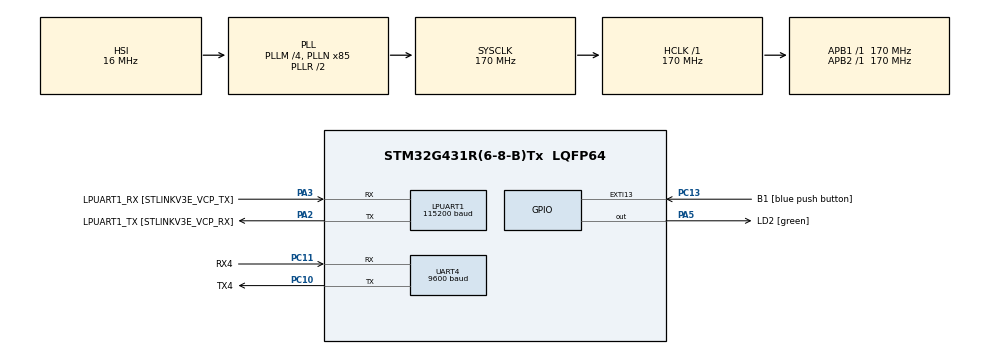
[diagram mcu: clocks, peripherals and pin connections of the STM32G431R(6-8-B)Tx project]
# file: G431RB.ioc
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Dma.Request0=UART4_RX
Dma.Request1=UART4_TX
Dma.UART4_RX.0.Direction=DMA_PERIPH_TO_MEMORY
Dma.UART4_RX.0.EventEnable=DISABLE
Dma.UART4_RX.0.Instance=DMA1_Channel1
Dma.UART4_RX.0.MemDataAlignment=DMA_MDATAALIGN_BYTE
Dma.UART4_RX.0.MemInc=DMA_MINC_ENABLE
Dma.UART4_RX.0.Mode=DMA_NORMAL
Dma.UART4_RX.0.PeriphDataAlignment=DMA_PDATAALIGN_BYTE
Dma.UART4_RX.0.PeriphInc=DMA_PINC_DISABLE
Dma.UART4_RX.0.Polarity=HAL_DMAMUX_REQ_GEN_RISING
Dma.UART4_RX.0.Priority=DMA_PRIORITY_LOW
Dma.UART4_RX.0.RequestNumber=1
Dma.UART4_RX.0.SignalID=NONE
Dma.UART4_RX.0.SyncEnable=DISABLE
Dma.UART4_RX.0.SyncPolarity=HAL_DMAMUX_SYNC_NO_EVENT
Dma.UART4_RX.0.SyncRequestNumber=1
Dma.UART4_RX.0.SyncSignalID=NONE
Dma.UART4_TX.1.Direction=DMA_MEMORY_TO_PERIPH
Dma.UART4_TX.1.EventEnable=DISABLE
Dma.UART4_TX.1.Instance=DMA1_Channel2
Dma.UART4_TX.1.MemDataAlignment=DMA_MDATAALIGN_BYTE
Dma.UART4_TX.1.MemInc=DMA_MINC_ENABLE
Dma.UART4_TX.1.Mode=DMA_NORMAL
Dma.UART4_TX.1.PeriphDataAlignment=DMA_PDATAALIGN_BYTE
Dma.UART4_TX.1.PeriphInc=DMA_PINC_DISABLE
Dma.UART4_TX.1.Polarity=HAL_DMAMUX_REQ_GEN_RISING
Dma.UART4_TX.1.Priority=DMA_PRIORITY_LOW
Dma.UART4_TX.1.RequestNumber=1
Dma.UART4_TX.1.SignalID=NONE
Dma.UART4_TX.1.SyncEnable=DISABLE
Dma.UART4_TX.1.SyncPolarity=HAL_DMAMUX_SYNC_NO_EVENT
Dma.UART4_TX.1.SyncRequestNumber=1
Dma.UART4_TX.1.SyncSignalID=NONE
LPUART1.BaudRate=115200
LPUART1.WordLength=UART_WORDLENGTH_8B
Mcu.Family=STM32G4
Mcu.Name=STM32G431R(6-8-B)Tx
Mcu.Package=LQFP64
NVIC.DMA1_Channel1_IRQn=true\:0\:0\:false\:false\:true\:false\:true\:true
NVIC.DMA1_Channel2_IRQn=true\:0\:0\:false\:false\:true\:false\:true\:true
NVIC.PriorityGroup=NVIC_PRIORITYGROUP_4
NVIC.UART4_IRQn=true\:0\:0\:false\:false\:true\:true\:true\:true
PA13.GPIO_Label=T_SWDIO
PA13.Mode=Serial_Wire
PA13.Signal=SYS_JTMS-SWDIO
PA14.GPIO_Label=T_SWCLK
PA14.Mode=Serial_Wire
PA14.Signal=SYS_JTCK-SWCLK
PA2.GPIO_Label=LPUART1_TX [STLINKV3E_VCP_RX]
PA2.Mode=Asynchronous
PA2.Signal=LPUART1_TX
PA3.GPIO_Label=LPUART1_RX [STLINKV3E_VCP_TX]
PA3.Mode=Asynchronous
PA3.Signal=LPUART1_RX
PA5.GPIO_Label=LD2 [green]
PA5.Signal=GPIO_Output
PB3.GPIO_Label=T_SWO
PB3.Signal=SYS_JTDO-SWO
PC10.GPIO_Label=TX4
PC10.Mode=Asynchronous
PC10.Signal=UART4_TX
PC11.GPIO_Label=RX4
PC11.GPIO_PuPd=GPIO_PULLUP
PC11.Mode=Asynchronous
PC11.Signal=UART4_RX
PC13.GPIO_Label=B1 [blue push button]
PC13.Signal=GPXTI13
PC14-OSC32_IN.Mode=LSE-External-Oscillator
PC14-OSC32_IN.Signal=RCC_OSC32_IN
PC15-OSC32_OUT.Mode=LSE-External-Oscillator
PC15-OSC32_OUT.Signal=RCC_OSC32_OUT
PF0-OSC_IN.Mode=HSE-External-Oscillator
PF0-OSC_IN.Signal=RCC_OSC_IN
PF1-OSC_OUT.Mode=HSE-External-Oscillator
PF1-OSC_OUT.Signal=RCC_OSC_OUT
ProjectManager.HeapSize=0x200
ProjectManager.StackSize=0x400
ProjectManager.TargetToolchain=MDK-ARM V5.32
RCC.ADC12Freq_Value=170000000
RCC.AHBFreq_Value=170000000
RCC.APB1Freq_Value=170000000
RCC.APB1TimFreq_Value=170000000
RCC.APB2Freq_Value=170000000
RCC.APB2TimFreq_Value=170000000
RCC.CortexFreq_Value=170000000
RCC.EXTERNAL_CLOCK_VALUE=12288000
RCC.HCLKFreq_Value=170000000
RCC.HSE_VALUE=24000000
RCC.HSI48_VALUE=48000000
RCC.HSI_VALUE=16000000
RCC.PLLM=RCC_PLLM_DIV4
RCC.PLLN=85
RCC.RTCClockSelection=RCC_RTCCLKSOURCE_LSE
RCC.SYSCLKFreq_VALUE=170000000
RCC.SYSCLKSource=RCC_SYSCLKSOURCE_PLLCLK
RCC.USBFreq_Value=170000000
RCC.VCOOutputFreq_Value=340000000
UART4.BaudRate=9600
VP_SYS_VS_DBSignals.Mode=DisableDeadBatterySignals
board=NUCLEO-G431RB

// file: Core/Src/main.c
/* USER CODE BEGIN Header */
/**
  ******************************************************************************
  * @file           : main.c
  * @brief          : Main program body
  ******************************************************************************
  * @attention
  *
  * Copyright (c) 2024 STMicroelectronics.
  * All rights reserved.
  *
  * This software is licensed under terms that can be found in the LICENSE file
  * in the root directory of this software component.
  * If no LICENSE file comes with this software, it is provided AS-IS.
  *
  ******************************************************************************
  */
/* USER CODE END Header */
#include "main.h"
#include "dma.h"
#include "usart.h"
#include "gpio.h"

/* USER CODE BEGIN Includes */
#include <stdio.h>
#include <string.h>
#pragma import(__use_no_semihosting)

struct __FILE
{
    int handle;
};                                                         // 标准库需要的支持函数

FILE __stdout;                                             // FILE 在stdio.h文件
void _sys_exit(int x)
{
    x = x;                                                 // 定义_sys_exit()以避免使用半主机模式
}
int fputc(int ch, FILE *f)                                 // 重写fputc函数，使printf的输出由UART1实现,  这里使用USART1
{
    // 注意，不能使用HAL_UART_Transmit_IT(), 机制上会冲突; 因为调用中断发送函数后，如果上次发送还在进行，就会直接返回！它不会继续等待，也不会数据填入队列排队发送
    HAL_UART_Transmit(&huart4, (uint8_t *)&ch, 1, 0x02);   // 使用HAL_UART_Transmit，相等于USART4->DR = ch, 函数内部加了简单的超时判断(ms)，防止卡死
    return ch;
}
/* USER CODE END Includes */

/* USER CODE BEGIN PTD */
xUSART_Typedef USART4= {0};
/* USER CODE END PTD */

void SystemClock_Config(void);

int main(void)
{

  /* MCU Configuration--------------------------------------------------------*/

  /* Reset of all peripherals, Initializes the Flash interface and the Systick. */
  HAL_Init();

  /* Configure the system clock */
  SystemClock_Config();

  /* Initialize all configured peripherals */
  MX_GPIO_Init();
  MX_DMA_Init();
  MX_LPUART1_UART_Init();
  MX_UART4_Init();

  /* Infinite loop */
  /* USER CODE BEGIN WHILE */
  while (1)
  {
		if (USART4.ReceiveNum > 0)
        {
            int num1, num2;
            sscanf((char*)USART4.ReceiveData, "%d %d", &num1, &num2);
            num1++;num2++;
            char sendData[512];
            snprintf(sendData, sizeof(sendData), "%d %d", num1, num2);
            printf("%s ", sendData);
            USART4.ReceiveNum = 0;
            memset(USART4.ReceiveData, 0, sizeof(USART4.ReceiveData));
        }
		HAL_Delay(1000);
				HAL_UARTEx_ReceiveToIdle_DMA(&huart4,USART4.BuffTemp,sizeof(USART4.BuffTemp));

  }
  /* USER CODE END 3 */
}

void SystemClock_Config(void)
{
  RCC_OscInitTypeDef RCC_OscInitStruct = {0};
  RCC_ClkInitTypeDef RCC_ClkInitStruct = {0};

  /** Configure the main internal regulator output voltage
  */
  HAL_PWREx_ControlVoltageScaling(PWR_REGULATOR_VOLTAGE_SCALE1_BOOST);

  /** Initializes the RCC Oscillators according to the specified parameters
  * in the RCC_OscInitTypeDef structure.
  */
  RCC_OscInitStruct.OscillatorType = RCC_OSCILLATORTYPE_HSI;
  RCC_OscInitStruct.HSIState = RCC_HSI_ON;
  RCC_OscInitStruct.HSICalibrationValue = RCC_HSICALIBRATION_DEFAULT;
  RCC_OscInitStruct.PLL.PLLState = RCC_PLL_ON;
  RCC_OscInitStruct.PLL.PLLSource = RCC_PLLSOURCE_HSI;
  RCC_OscInitStruct.PLL.PLLM = RCC_PLLM_DIV4;
  RCC_OscInitStruct.PLL.PLLN = 85;
  RCC_OscInitStruct.PLL.PLLP = RCC_PLLP_DIV2;
  RCC_OscInitStruct.PLL.PLLQ = RCC_PLLQ_DIV2;
  RCC_OscInitStruct.PLL.PLLR = RCC_PLLR_DIV2;
  if (HAL_RCC_OscConfig(&RCC_OscInitStruct) != HAL_OK)
  {
    Error_Handler();
  }

  /** Initializes the CPU, AHB and APB buses clocks
  */
  RCC_ClkInitStruct.ClockType = RCC_CLOCKTYPE_HCLK|RCC_CLOCKTYPE_SYSCLK
                              |RCC_CLOCKTYPE_PCLK1|RCC_CLOCKTYPE_PCLK2;
  RCC_ClkInitStruct.SYSCLKSource = RCC_SYSCLKSOURCE_PLLCLK;
  RCC_ClkInitStruct.AHBCLKDivider = RCC_SYSCLK_DIV1;
  RCC_ClkInitStruct.APB1CLKDivider = RCC_HCLK_DIV1;
  RCC_ClkInitStruct.APB2CLKDivider = RCC_HCLK_DIV1;

  if (HAL_RCC_ClockConfig(&RCC_ClkInitStruct, FLASH_LATENCY_4) != HAL_OK)
  {
    Error_Handler();
  }
}

void Error_Handler(void)
{
  __disable_irq();
  while (1)
  {
  }
}
